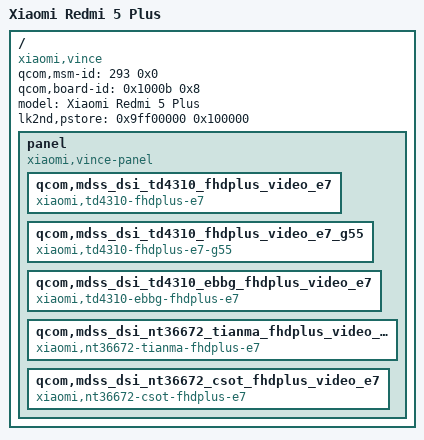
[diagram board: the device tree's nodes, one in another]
// SPDX-License-Identifier: GPL-2.0-only

/dts-v1/;

/include/ "msm8953.dtsi"

/ {
	// This is used by the bootloader to find the correct DTB 
	qcom,msm-id = <293 0x0>;
	qcom,board-id= <0x1000b 0x8>;

	model = "Xiaomi Redmi 5 Plus";
	compatible = "xiaomi,vince", "qcom,msm8953", "lk2nd,device";
	lk2nd,pstore = <0x9ff00000 0x100000>;

	panel {
		compatible = "xiaomi,vince-panel";
		qcom,mdss_dsi_td4310_fhdplus_video_e7 {
			compatible = "xiaomi,td4310-fhdplus-e7";
		};
		qcom,mdss_dsi_td4310_fhdplus_video_e7_g55 {
			compatible = "xiaomi,td4310-fhdplus-e7-g55";
		};
		qcom,mdss_dsi_td4310_ebbg_fhdplus_video_e7 {
			compatible = "xiaomi,td4310-ebbg-fhdplus-e7";
		};
		qcom,mdss_dsi_nt36672_tianma_fhdplus_video_e7 {
			compatible = "xiaomi,nt36672-tianma-fhdplus-e7";
		};
		qcom,mdss_dsi_nt36672_csot_fhdplus_video_e7 {
			compatible = "xiaomi,nt36672-csot-fhdplus-e7";
		};
	};
};
